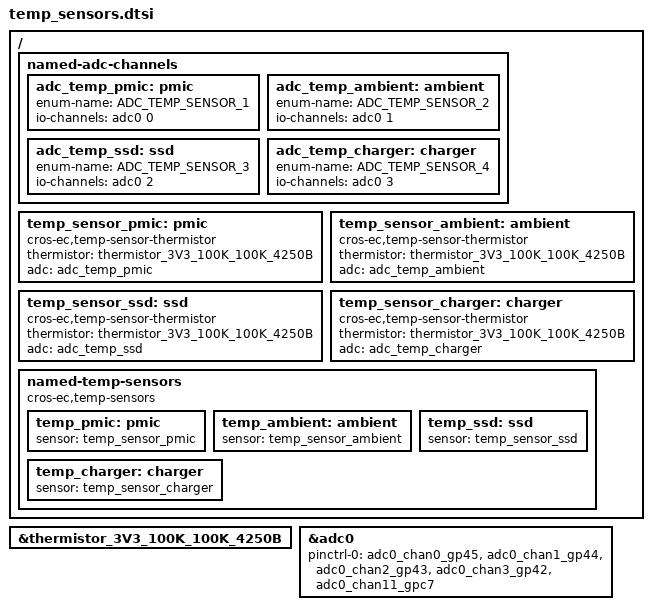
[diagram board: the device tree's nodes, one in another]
/* Copyright 2025 The ChromiumOS Authors
 * Use of this source code is governed by a BSD-style license that can be
 * found in the LICENSE file.
 */

#include <cros/thermistor/thermistor.dtsi>

/ {
	named-adc-channels {

		adc_temp_pmic: pmic {
			enum-name = "ADC_TEMP_SENSOR_1";
			io-channels = <&adc0 0>;
		};
		adc_temp_ambient: ambient {
			enum-name = "ADC_TEMP_SENSOR_2";
			io-channels = <&adc0 1>;
		};
		adc_temp_ssd: ssd {
			enum-name = "ADC_TEMP_SENSOR_3";
			io-channels = <&adc0 2>;
		};
		adc_temp_charger: charger {
			enum-name = "ADC_TEMP_SENSOR_4";
			io-channels = <&adc0 3>;
		};
	};

	temp_sensor_pmic: pmic {
		compatible = "cros-ec,temp-sensor-thermistor";
		thermistor = <&thermistor_3V3_100K_100K_4250B>;
		adc = <&adc_temp_pmic>;
	};
	temp_sensor_ambient: ambient {
		compatible = "cros-ec,temp-sensor-thermistor";
		thermistor = <&thermistor_3V3_100K_100K_4250B>;
		adc = <&adc_temp_ambient>;
	};
	temp_sensor_ssd: ssd {
		compatible = "cros-ec,temp-sensor-thermistor";
		thermistor = <&thermistor_3V3_100K_100K_4250B>;
		adc = <&adc_temp_ssd>;
	};
	temp_sensor_charger: charger {
		compatible = "cros-ec,temp-sensor-thermistor";
		thermistor = <&thermistor_3V3_100K_100K_4250B>;
		adc = <&adc_temp_charger>;
	};

	named-temp-sensors {
		compatible = "cros-ec,temp-sensors";
		temp_pmic: pmic {
			sensor = <&temp_sensor_pmic>;
		};
		temp_ambient: ambient {
			sensor = <&temp_sensor_ambient>;
		};
		temp_ssd: ssd {
			sensor = <&temp_sensor_ssd>;
		};
		temp_charger: charger {
			sensor = <&temp_sensor_charger>;
		};
	};
};

&thermistor_3V3_100K_100K_4250B {
	status = "okay";
};

&adc0 {
	pinctrl-0 = <&adc0_chan0_gp45
		&adc0_chan1_gp44
		&adc0_chan2_gp43
		&adc0_chan3_gp42
		&adc0_chan11_gpc7>;
	pinctrl-names = "default";
};
